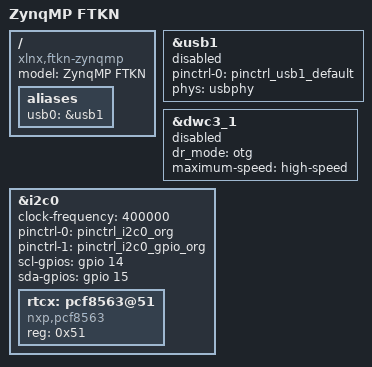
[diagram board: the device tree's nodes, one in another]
/dts-v1/;

#include "ftkn-zynqmp.dtsi"

/ {
	model = "ZynqMP FTKN";
	compatible = "xlnx,ftkn-zynqmp", "xlnx,zynqmp";

    aliases {
        usb0 = &usb1;
    };
};

&usb1 {
	status = "disabled";
	pinctrl-names = "default";
	pinctrl-0 = <&pinctrl_usb1_default>;
	phy-names = "usb2-phy";
    phys = <&usbphy>;
};

&dwc3_1 {
	status = "disabled";
	dr_mode = "otg";
    maximum-speed = "high-speed";
};

&i2c0 {
	status = "okay";
	clock-frequency = <400000>;
	pinctrl-names = "default", "gpio";
	pinctrl-0 = <&pinctrl_i2c0_org>;
	pinctrl-1 = <&pinctrl_i2c0_gpio_org>;
	scl-gpios = <&gpio 14 GPIO_ACTIVE_HIGH>;
	sda-gpios = <&gpio 15 GPIO_ACTIVE_HIGH>;

	rtcx: pcf8563@51 {
		reg = <0x51>;
		compatible = "nxp,pcf8563";
	};
};
